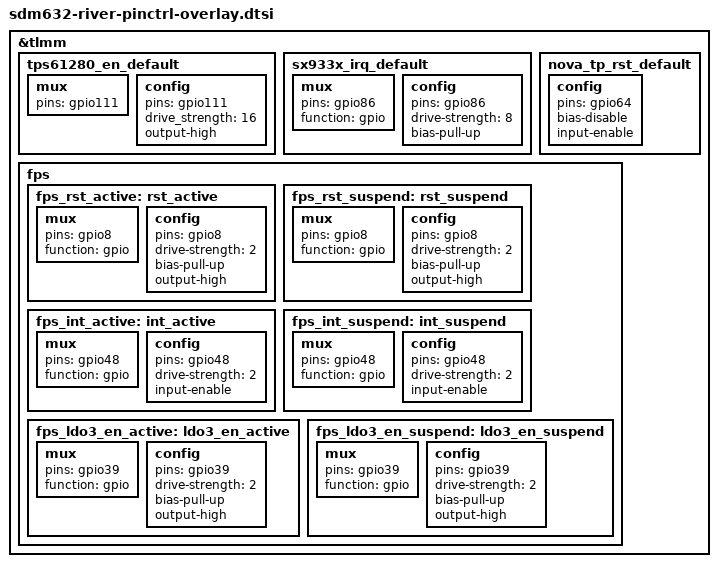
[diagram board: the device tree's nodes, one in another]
/*
 * Copyright (c) 2017-2018, The Linux Foundation. All rights reserved.
 *
 * This program is free software; you can redistribute it and/or modify
 * it under the terms of the GNU General Public License version 2 and
 * only version 2 as published by the Free Software Foundation.
 *
 * This program is distributed in the hope that it will be useful,
 * but WITHOUT ANY WARRANTY; without even the implied warranty of
 * MERCHANTABILITY or FITNESS FOR A PARTICULAR PURPOSE.  See the
 * GNU General Public License for more details.
 */

&tlmm {
	tps61280_en_default: tps61280_en_default {
		mux {
			pins = "gpio111";
		};
		config {
			pins = "gpio111";
			drive_strength = <16>;
			output-high;
		};
	};

	sx933x_irq_default: sx933x_irq_default {
		mux {
			pins = "gpio86";
			function = "gpio";
		};
		config {
			pins = "gpio86";
			drive-strength = <8>;
			bias-pull-up;
		};
	};

	nova_tp_rst_default: nova_tp_rst_default {
		config {
			pins = "gpio64";
			bias-disable;
			input-enable;
		};
	};

	fps: fps {
		fps_rst_active: rst_active {
			/* RESET */
			mux {
				pins = "gpio8";
				function = "gpio";
			};

			config {
				pins = "gpio8";
				drive-strength = <2>; /* 2 MA */
				bias-pull-up; /* pull up */
				output-high;
			};
		};

		fps_rst_suspend: rst_suspend {
			/* RESET */
			mux {
				pins = "gpio8";
				function = "gpio";
			};

			config {
				pins = "gpio8";
				drive-strength = <2>; /* 2 MA */
				bias-pull-up; /* pull up */
				output-high;
			};
		};

		fps_int_active: int_active {
			/* INTERRUPT */
			mux {
				pins = "gpio48";
				function = "gpio";
			};

			config {
				pins = "gpio48";
				drive-strength = <2>; /* 2 MA */
				input-enable;
			};
		};

		fps_int_suspend: int_suspend {
			/* INTERRUPT */
			mux {
				pins = "gpio48";
				function = "gpio";
			};

			config {
				pins = "gpio48";
				drive-strength = <2>; /* 2 MA */
				input-enable;
			};
		};

		fps_ldo3_en_active: ldo3_en_active {
			/* LDO3_EN */
			mux {
				pins = "gpio39";
				function = "gpio";
			};

			config {
				pins = "gpio39";
				drive-strength = <2>; /* 2 MA */
				bias-pull-up; /* pull up */
				output-high;
			};
		};

		fps_ldo3_en_suspend: ldo3_en_suspend {
			/* LDO3_EN */
			mux {
				pins = "gpio39";
				function = "gpio";
			};

			config {
				pins = "gpio39";
				drive-strength = <2>; /* 2 MA */
				bias-pull-up; /* pull up */
				output-high;
			};
		};
	};
};
